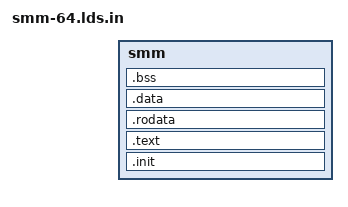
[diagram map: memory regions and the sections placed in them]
/***************************************************************************
 * Broadcom Proprietary and Confidential. (c)2016 Broadcom. All rights reserved.
 *
 *  THIS SOFTWARE MAY ONLY BE USED SUBJECT TO AN EXECUTED SOFTWARE LICENSE
 *  AGREEMENT  BETWEEN THE USER AND BROADCOM.  YOU HAVE NO RIGHT TO USE OR
 *  EXPLOIT THIS MATERIAL EXCEPT SUBJECT TO THE TERMS OF SUCH AN AGREEMENT.
 *
 ***************************************************************************/

/* smm-64.lds.in */

MEMORY {
	smm : ORIGIN = @PSCI_BASE@, LENGTH = @PSCI_SIZE@
}

ENTRY(smm_start)

SECTIONS {
	.init :
	{
		smm_start = .;
		* (.init*)
	} > smm =@FILLB@

	.text :
	{
		* (.text*)
	} > smm =@FILLB@

	.rodata :
	{
		* (.rodata)
		* (.rodata.*)
	} > smm =@FILLB@

	.data :
	{
		* (.data*)
		. = ALIGN(16);
	} > smm =@FILLB@

	.bss :
	{
		_smm_zero_start = .;
		* (.bss*)
		* (.sbss*)
		. = ALIGN(4);
		_smm_zero_end = .;
	} > smm =0x00

	. += 3;
	. = ALIGN(64);
	 __config_info = .;

	/* force __config_info != __per_cpu_info */
	. += 3;
	. = ALIGN(64);
	__per_cpu_info = .;
};

/* EOF */
